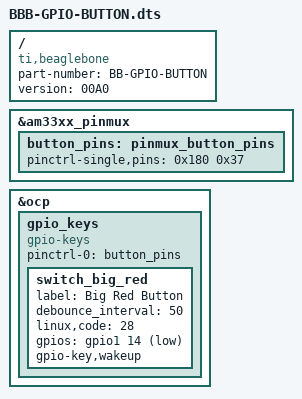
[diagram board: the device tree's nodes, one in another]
/dts-v1/;
/plugin/;

/ {
    compatible = "ti,beaglebone", "ti,beaglebone-black";

    /* identification */
    part-number = "BB-GPIO-BUTTON";
    version = "00A0";

    fragment@0 {
        target = <&am33xx_pinmux>;
        __overlay__ {
            button_pins: pinmux_button_pins{
                pinctrl-single,pins = <
                    0x180 0x37 // P9_26 = End stop X2  = GPIO0_14
                >;
            };
        };
    };

    fragment@1 {
        target = <&ocp>;
        __overlay__ {            
            #address-cells = <1>;
            #size-cells = <1>;                            

            gpio_keys {
                compatible = "gpio-keys";
                pinctrl-names = "default";
                pinctrl-0 = <&button_pins>;
                #address-cells = <1>;
                #size-cells = <0>;

                switch_big_red {
                    label = "Big Red Button";
                    debounce_interval = <50>;
                    linux,code = <28>;
                    gpios = <&gpio1 14 0x5>;
                    gpio-key,wakeup;
                };
            };
        };
    };
};
